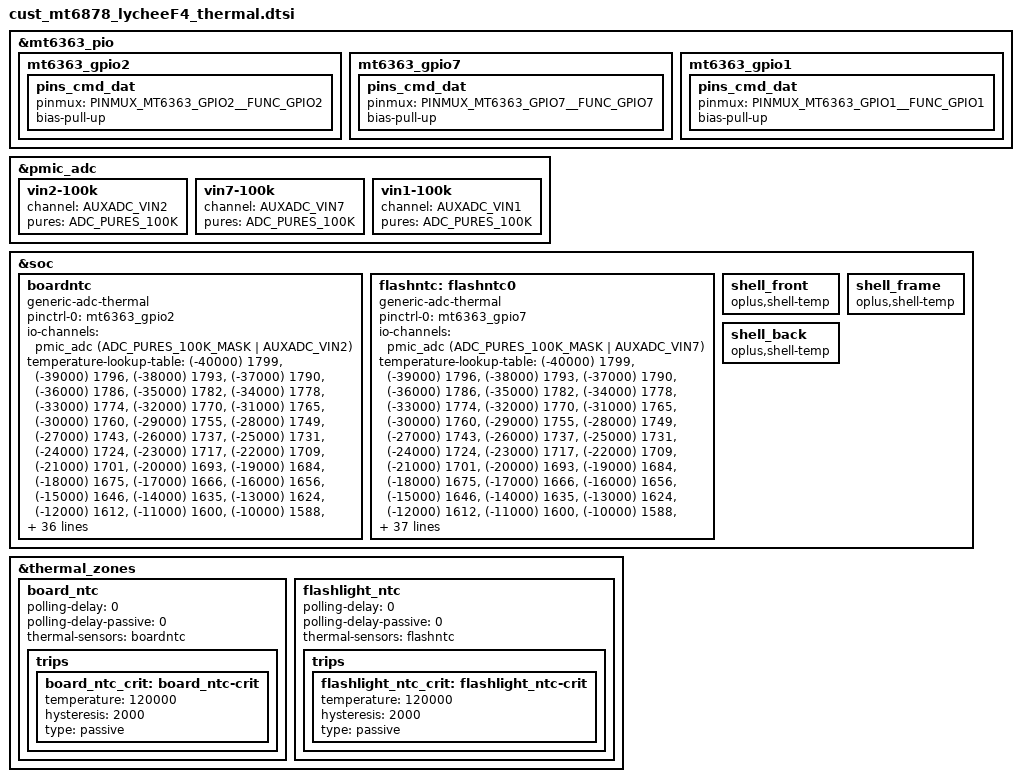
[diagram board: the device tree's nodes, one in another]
#include <dt-bindings/iio/mt635x-auxadc.h>
#include <dt-bindings/pinctrl/mt6363-pinfunc.h>

&mt6363_pio {
	mt6363_gpio2: mt6363_gpio2 {
		pins_cmd_dat {
			pinmux = <PINMUX_MT6363_GPIO2__FUNC_GPIO2>;
			bias-pull-up;
		};
	};
	mt6363_gpio7: mt6363_gpio7 {
		pins_cmd_dat {
			pinmux = <PINMUX_MT6363_GPIO7__FUNC_GPIO7>;
			bias-pull-up;
		};
	};
	mt6363_gpio1: mt6363_gpio1 {
		pins_cmd_dat {
			pinmux = <PINMUX_MT6363_GPIO1__FUNC_GPIO1>;
			bias-pull-up;
		};
	};
};

&pmic_adc {
	vin2-100k {
		channel = <AUXADC_VIN2>;
		pures = <ADC_PURES_100K>;
	};
	vin7-100k {
		channel = <AUXADC_VIN7>;
		pures = <ADC_PURES_100K>;
	};
	vin1-100k {
		channel = <AUXADC_VIN1>;
		pures = <ADC_PURES_100K>;
	};
};

&soc {
	boardntc: boardntc {
		compatible = "generic-adc-thermal";
		#thermal-sensor-cells = <0>;
		pinctrl-names = "board_gpio2";
		pinctrl-0 = <&mt6363_gpio2>;
		io-channels = <&pmic_adc (ADC_PURES_100K_MASK | AUXADC_VIN2)>;
		io-channel-names = "sensor-channel";
		temperature-lookup-table =
			<(-40000) 1799>,
			<(-39000) 1796>,
			<(-38000) 1793>,
			<(-37000) 1790>,
			<(-36000) 1786>,
			<(-35000) 1782>,
			<(-34000) 1778>,
			<(-33000) 1774>,
			<(-32000) 1770>,
			<(-31000) 1765>,
			<(-30000) 1760>,
			<(-29000) 1755>,
			<(-28000) 1749>,
			<(-27000) 1743>,
			<(-26000) 1737>,
			<(-25000) 1731>,
			<(-24000) 1724>,
			<(-23000) 1717>,
			<(-22000) 1709>,
			<(-21000) 1701>,
			<(-20000) 1693>,
			<(-19000) 1684>,
			<(-18000) 1675>,
			<(-17000) 1666>,
			<(-16000) 1656>,
			<(-15000) 1646>,
			<(-14000) 1635>,
			<(-13000) 1624>,
			<(-12000) 1612>,
			<(-11000) 1600>,
			<(-10000) 1588>,
			<(-9000) 1575>,
			<(-8000) 1561>,
			<(-7000) 1547>,
			<(-6000)1533>,
			<(-5000) 1518>,
			<(-4000) 1503>,
			<(-3000) 1487>,
			<(-2000) 1471>,
			<(-1000) 1454>,
			<0 1437>,
			<1000 1420>,
			<2000 1402>,
			<3000 1384>,
			<4000 1365>,
			<5000 1346>,
			<6000 1327>,
			<7000 1307>,
			<8000 1287>,
			<9000 1267>,
			<10000 1246>,
			<11000 1225>,
			<12000 1204>,
			<13000 1183>,
			<14000 1161>,
			<15000 1139>,
			<16000 1118>,
			<17000 1096>,
			<18000 1074>,
			<19000 1052>,
			<20000 1030>,
			<21000 1008>,
			<22000 986>,
			<23000 964>,
			<24000 942>,
			<25000 920>,
			<26000 898>,
			<27000 877>,
			<28000 855>,
			<29000 834>,
			<30000 813>,
			<31000 793>,
			<32000 772>,
			<33000 752>,
			<34000 732>,
			<35000 712>,
			<36000 693>,
			<37000 674>,
			<38000 655>,
			<39000 637>,
			<40000 619>,
			<41000 601>,
			<42000 584>,
			<43000 567>,
			<44000 550>,
			<45000 534>,
			<46000 518>,
			<47000 503>,
			<48000 488>,
			<49000 473>,
			<50000 459>,
			<51000 445>,
			<52000 431>,
			<53000 418>,
			<54000 405>,
			<55000 392>,
			<56000 380>,
			<57000 368>,
			<58000 357>,
			<59000 345>,
			<60000 335>,
			<61000 324>,
			<62000 314>,
			<63000 304>,
			<64000 294>,
			<65000 285>,
			<66000 276>,
			<67000 267>,
			<68000 259>,
			<69000 250>,
			<70000 243>,
			<71000 235>,
			<72000 227>,
			<73000 220>,
			<74000 213>,
			<75000 206>,
			<76000 200>,
			<77000 194>,
			<78000 187>,
			<79000 182>,
			<80000 176>,
			<81000 170>,
			<82000 165>,
			<83000 160>,
			<84000 155>,
			<85000 150>,
			<86000 145>,
			<87000 141>,
			<88000 136>,
			<89000 132>,
			<90000 128>,
			<91000 124>,
			<92000 120>,
			<93000 117>,
			<94000 113>,
			<95000 110>,
			<96000 106>,
			<97000 103>,
			<98000 100>,
			<99000 97>,
			<100000 94>,
			<101000 91>,
			<102000 88>,
			<103000 86>,
			<104000 83>,
			<105000 81>,
			<106000 78>,
			<107000 76>,
			<108000 74>,
			<109000 72>,
			<110000 70>,
			<111000 68>,
			<112000 66>,
			<113000 64>,
			<114000 62>,
			<115000 60>,
			<116000 58>,
			<117000 57>,
			<118000 55>,
			<119000 54>,
			<120000 52>,
			<121000 51>,
			<122000 49>,
			<123000 48>,
			<124000 47>,
			<125000 45>;
	};

	flashntc: flashntc0 {
		compatible = "generic-adc-thermal";
		#thermal-sensor-cells = <0>;
		pinctrl-names = "board_gpio7";
		pinctrl-0 = <&mt6363_gpio7>;
		io-channels = <&pmic_adc (ADC_PURES_100K_MASK | AUXADC_VIN7)>;
		io-channel-names = "sensor-channel";
		temperature-lookup-table =
			<(-40000) 1799>,
			<(-39000) 1796>,
			<(-38000) 1793>,
			<(-37000) 1790>,
			<(-36000) 1786>,
			<(-35000) 1782>,
			<(-34000) 1778>,
			<(-33000) 1774>,
			<(-32000) 1770>,
			<(-31000) 1765>,
			<(-30000) 1760>,
			<(-29000) 1755>,
			<(-28000) 1749>,
			<(-27000) 1743>,
			<(-26000) 1737>,
			<(-25000) 1731>,
			<(-24000) 1724>,
			<(-23000) 1717>,
			<(-22000) 1709>,
			<(-21000) 1701>,
			<(-20000) 1693>,
			<(-19000) 1684>,
			<(-18000) 1675>,
			<(-17000) 1666>,
			<(-16000) 1656>,
			<(-15000) 1646>,
			<(-14000) 1635>,
			<(-13000) 1624>,
			<(-12000) 1612>,
			<(-11000) 1600>,
			<(-10000) 1588>,
			<(-9000) 1575>,
			<(-8000) 1562>,
			<(-7000) 1548>,
			<(-6000) 1533>,
			<(-5000) 1519>,
			<(-4000) 1503>,
			<(-3000) 1488>,
			<(-2000) 1472>,
			<(-1000) 1455>,
			<0 1438>,
			<1000 1421>,
			<2000 1403>,
			<3000 1385>,
			<4000 1366>,
			<5000 1347>,
			<6000 1328>,
			<7000 1308>,
			<8000 1289>,
			<9000 1268>,
			<10000 1248>,
			<11000 1227>,
			<12000 1206>,
			<13000 1185>,
			<14000 1164>,
			<15000 1142>,
			<16000 1120>,
			<17000 1099>,
			<18000 1077>,
			<19000 1055>,
			<20000 1033>,
			<21000 1011>,
			<22000 990>,
			<23000 968>,
			<24000 946>,
			<25000 925>,
			<26000 903>,
			<27000 882>,
			<28000 861>,
			<29000 840>,
			<30000 819>,
			<31000 799>,
			<32000 778>,
			<33000 758>,
			<34000 739>,
			<35000 719>,
			<36000 700>,
			<37000 681>,
			<38000 663>,
			<39000 645>,
			<40000 627>,
			<41000 609>,
			<42000 592>,
			<43000 576>,
			<44000 559>,
			<45000 543>,
			<46000 528>,
			<47000 512>,
			<48000 498>,
			<49000 483>,
			<50000 469>,
			<51000 455>,
			<52000 442>,
			<53000 429>,
			<54000 416>,
			<55000 404>,
			<56000 392>,
			<57000 380>,
			<58000 368>,
			<59000 357>,
			<60000 347>,
			<61000 336>,
			<62000 326>,
			<63000 317>,
			<64000 307>,
			<65000 298>,
			<66000 289>,
			<67000 280>,
			<68000 272>,
			<69000 264>,
			<70000 256>,
			<71000 249>,
			<72000 241>,
			<73000 234>,
			<74000 227>,
			<75000 221>,
			<76000 214>,
			<77000 208>,
			<78000 202>,
			<79000 196>,
			<80000 191>,
			<81000 185>,
			<82000 180>,
			<83000 175>,
			<84000 170>,
			<85000 165>,
			<86000 161>,
			<87000 156>,
			<88000 152>,
			<89000 148>,
			<90000 144>,
			<91000 140>,
			<92000 136>,
			<93000 133>,
			<94000 129>,
			<95000 126>,
			<96000 122>,
			<97000 119>,
			<98000 116>,
			<99000 113>,
			<100000 110>,
			<101000 108>,
			<102000 105>,
			<103000 102>,
			<104000 100>,
			<105000 97>,
			<106000 95>,
			<107000 93>,
			<108000 91>,
			<109000 89>,
			<110000 87>,
			<111000 85>,
			<112000 83>,
			<113000 81>,
			<114000 79>,
			<115000 77>,
			<116000 76>,
			<117000 74>,
			<118000 72>,
			<119000 71>,
			<120000 69>,
			<121000 68>,
			<122000 67>,
			<123000 65>,
			<124000 64>,
			<125000 63>;
	};



	//#ifdef OPLUS_FEATURE_POWER_THERMAL
	shell_front {
		compatible = "oplus,shell-temp";
	};

	shell_frame {
		compatible = "oplus,shell-temp";
	};

	shell_back {
		compatible = "oplus,shell-temp";
	};
	//#endif /* OPLUS_FEATURE_POWER_THERMAL */
};

&thermal_zones {
	board_ntc: board_ntc {
		polling-delay = <0>; /* milliseconds */
		polling-delay-passive = <0>; /* milliseconds */
		thermal-sensors = <&boardntc>;
        trips {
			board_ntc_crit: board_ntc-crit {
				temperature = <120000>;
				hysteresis = <2000>;
				type = "passive";
			};
        };
	};

	flashlight_ntc: flashlight_ntc {
		polling-delay = <0>; /* milliseconds */
		polling-delay-passive = <0>; /* milliseconds */
		thermal-sensors = <&flashntc>;
		trips {
			flashlight_ntc_crit: flashlight_ntc-crit {
				temperature = <120000>;
				hysteresis = <2000>;
				type = "passive";
			};
		};
	};

};
